# AST1080 register map
File version: 1.0
CPU: CM4 r0p1, little endian, MPU, FPU, 4 interrupt priority bits, 256 interrupts
Registers are 32-bit, read-write, reset 0x0 unless marked. A register's access mark holds for its fields unless they carry their own. Offsets are from the block's base; [hi:lo] are bit positions; 'fields as' and 'values as' point back to an identical list.

## uhci
Base 0x74110000
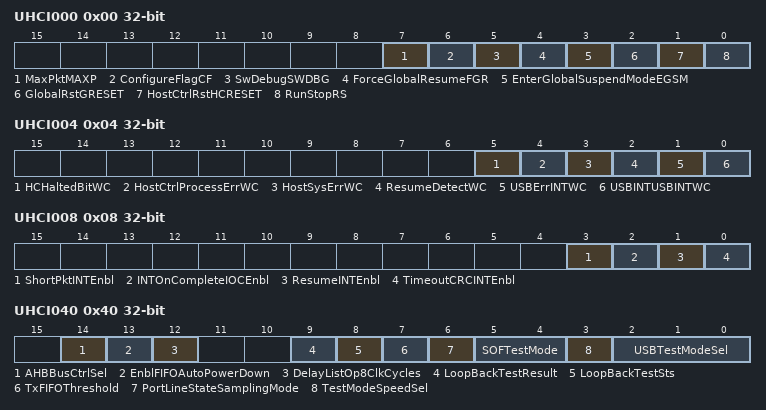
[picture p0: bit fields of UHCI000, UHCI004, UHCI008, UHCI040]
0x00 UHCI000 — USB Command Register (USBCMD)
  [7] MaxPktMAXP — Max Packet (MAXP)
    0=32_Bytes; 1=64_Bytes
  [6] ConfigureFlagCF
  [5] SwDebugSWDBG — Software Debug (SWDBG)
    0=Normal_Mode; 1=Debug_Mode
  [4] ForceGlobalResumeFGR
  [3] EnterGlobalSuspendModeEGSM
  [2] GlobalRstGRESET — Global Reset (GRESET)
  [1] HostCtrlRstHCRESET — Host Controller Reset (HCRESET)
  [0] RunStopRS
    0=Stop; 1=Run
0x04 UHCI004 — USB Status Register (USBSTS)
  [5] HCHaltedBitWC
  [4] HostCtrlProcessErrWC — Host Controller Process Error (WC)
  [3] HostSysErrWC — Host System Error (WC)
  [2] ResumeDetectWC
  [1] USBErrINTWC — USB Error Interrupt (WC)
  [0] USBINTUSBINTWC — USB Interrupt (USBINT) (WC)
0x08 UHCI008 — USB Interrupt Enable Register (USBINT)
  [all] fields
    0=Disabled; 1=Enabled
  [3] ShortPktINTEnbl — Short Packet Interrupt Enable
  [2] INTOnCompleteIOCEnbl — Interrupt On Complete (IOC) Enable
  [1] ResumeINTEnbl — Resume Interrupt Enable
  [0] TimeoutCRCINTEnbl — Timeout/CRC Interrupt Enable
0x0C UHCI00C — Frame List Based Address Register (FRBASEADD)
  [31:12] BaseAddr — Base Address
0x40 UHCI040 — Test Control Register
  [14] AHBBusCtrlSel — AHB Bus control selection
  [13] EnblFIFOAutoPowerDown — Enable FIFO Auto Power Down
    0=Disable; 1=Enable
  [12] DelayListOp8ClkCycles — Delay List operation 8 clock cycles
    0=No_Delay; 1=Delay_8_Cycles
  [9] LoopBackTestResult ro
    0=Fail; 1=Pass
  [8] LoopBackTestSts ro — Loop Back test status
    0=Not_Finish; 1=Finished
  [7] TxFIFOThreshold — Transmit FIFO threshold
    0=32_Bytes; 1=64_Bytes
  [6] PortLineStateSamplingMode
    0=Normal_Sample_At_EOF2; 1=Real_Time
  [5:4] SOFTestMode
    0=1_Ms_Normal_Mode; 1=64_Us; 2=128_Us; 3=256_Us
  [3] TestModeSpeedSel — Test Mode speed selection
    0=Full_Speed; 1=Low_Speed
  [2:0] USBTestModeSel — USB Test Mode selection
    0=Disable; 1=Enable_Test_J; 2=Enable_Test_K; 4=Enable_Test_Packet; 5=Enable_Test_SE0; 6=Enable_Test_SE1; 7=Enable_Test_Loop_Back_Regdebug (Enable Test Loop Back egdebug)
0x80 UHCI080 — Frame Number Register (FRNUM)
  [10:0] FrameListCurIndexFrameNumber — Frame List Current Index/Frame Number
0x84 UHCI084 reset 0x40 — Start of Frame Modify Register (SOFMOD)
  [6:0] SOFTimingValue
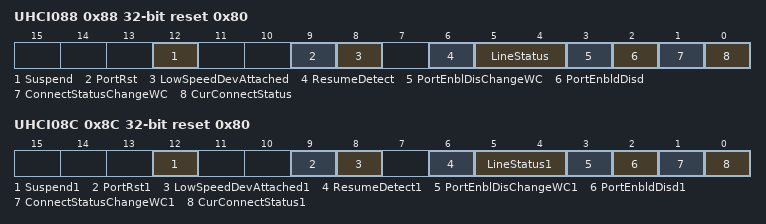
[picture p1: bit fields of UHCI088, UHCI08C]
0x88 UHCI088 reset 0x80 — Port1 Status/Control Register (PORTSC1)
  [12] Suspend
    0=Port_Not_In_Suspend_State; 1=Port_In_Suspend_State
  [9] PortRst — Port Reset
    0=Port_Is_Not_In_Reset; 1=Port_Is_In_Reset
  [8] LowSpeedDevAttached ro — Low Speed Device Attached
    0=Full_Speed_Device; 1=Low_Speed_Device_Is_Attached_To_This_Port
  [6] ResumeDetect
    0=No_Resume_Kstate_Detecteddriven_On_Port; 1=Resume_Detecteddriven_On_Port
  [5:4] LineStatus ro
  [3] PortEnblDisChangeWC — Port Enable/Disable Change (WC)
    0=No_Change; 1=Port_Enableddisabled_Status_Has_Changed
  [2] PortEnbldDisd — Port Enabled/Disabled
    0=Disable; 1=Enable
  [1] ConnectStatusChangeWC
    0=No_Change; 1=Change_In_Current_Connect_Status
  [0] CurConnectStatus ro — Current Connect Status
    0=No_Device_Is_Present; 1=Device_Is_Present_On_Port
0x8C UHCI08C reset 0x80 — Port2 Status/Control Register (PORTSC2)
  [12] Suspend1 — Suspend
    0=Port_Not_In_Suspend_State; 1=Port_In_Suspend_State
  [9] PortRst1 — Port Reset
    0=Port_Is_Not_In_Reset; 1=Port_Is_In_Reset
  [8] LowSpeedDevAttached1 ro — Low Speed Device Attached
    values as UHCI088.LowSpeedDevAttached
  [6] ResumeDetect1 — Resume Detect
    values as UHCI088.ResumeDetect
  [5:4] LineStatus1 ro — Line Status
  [3] PortEnblDisChangeWC1 — Port Enable/Disable Change (WC)
    0=No_Change; 1=Port_Enableddisabled_Status_Has_Changed
  [2] PortEnbldDisd1 — Port Enabled/Disabled
    0=Disable; 1=Enable
  [1] ConnectStatusChangeWC1 — Connect Status Change (WC)
    0=No_Change; 1=Change_In_Current_Connect_Status
  [0] CurConnectStatus1 ro — Current Connect Status
    0=No_Device_Is_Present; 1=Device_Is_Present_On_Port
